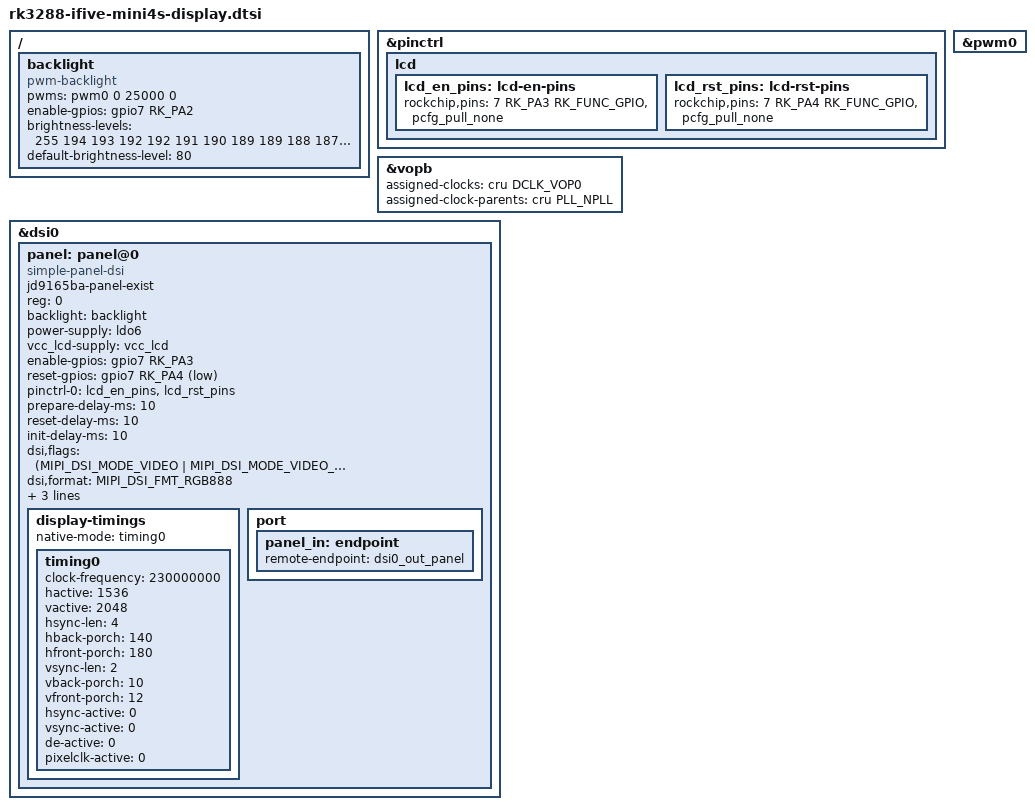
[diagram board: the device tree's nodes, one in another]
// SPDX-License-Identifier: (GPL-2.0+ OR MIT)
/*
 * iFive mini 4S display: backlight, panel power/reset pins, VOPB and the
 * JD9165BA DSI panel.  Included by rk3288-ifive-mini4s.dts.
 */

#include <dt-bindings/display/drm_mipi_dsi.h>
#include <dt-bindings/gpio/gpio.h>

/ {
	backlight: backlight {
		compatible = "pwm-backlight";
		status = "okay";
		pwms = <&pwm0 0 25000 0>;
		enable-gpios = <&gpio7 RK_PA2 GPIO_ACTIVE_HIGH>;
		/*
		 * Inverted drive (duty = 255 - level). The LED driver stays dark
		 * at level 56 and below and lights from about 60 (camera, 2026-11-15);
		 * 4.19 pwm_bl has no min-brightness, so the table holds the floor:
		 * index 0 = off, 1..255 span levels 61..255.
		 */
		brightness-levels = <
			255 194 193 192 192 191 190 189 189 188 187 186 186 185 184 183
			183 182 181 180 179 179 178 177 176 176 175 174 173 173 172 171
			170 170 169 168 167 167 166 165 164 163 163 162 161 160 160 159
			158 157 157 156 155 154 154 153 152 151 150 150 149 148 147 147
			146 145 144 144 143 142 141 141 140 139 138 137 137 136 135 134
			134 133 132 131 131 130 129 128 128 127 126 125 124 124 123 122
			121 121 120 119 118 118 117 116 115 115 114 113 112 112 111 110
			109 108 108 107 106 105 105 104 103 102 102 101 100  99  99  98
			 97  96  95  95  94  93  92  92  91  90  89  89  88  87  86  86
			 85  84  83  82  82  81  80  79  79  78  77  76  76  75  74  73
			 73  72  71  70  70  69  68  67  66  66  65  64  63  63  62  61
			 60  60  59  58  57  57  56  55  54  53  53  52  51  50  50  49
			 48  47  47  46  45  44  44  43  42  41  40  40  39  38  37  37
			 36  35  34  34  33  32  31  31  30  29  28  27  27  26  25  24
			 24  23  22  21  21  20  19  18  18  17  16  15  15  14  13  12
			 11  11  10   9   8   8   7   6   5   5   4   3   2   2   1   0
		>;
		default-brightness-level = <80>;
	};
};

&pinctrl {
	lcd {
		lcd_en_pins: lcd-en-pins {
			rockchip,pins = <7 RK_PA3 RK_FUNC_GPIO &pcfg_pull_none>;
		};

		lcd_rst_pins: lcd-rst-pins {
			rockchip,pins = <7 RK_PA4 RK_FUNC_GPIO &pcfg_pull_none>;
		};
	};
};

&pwm0 {
	status = "okay";
};

/*
 * dclk_vop0 from NPLL (460 MHz / 2 = 230 MHz pixel clock); GPLL (594 MHz)
 * has no integer divider that gives 230 MHz.
 */
&vopb {
	assigned-clocks = <&cru DCLK_VOP0>;
	assigned-clock-parents = <&cru PLL_NPLL>;
	status = "okay";
};

&dsi0 {
	panel: panel@0 {
		jd9165ba-panel-exist;
		compatible = "simple-panel-dsi";
		reg = <0>;
		backlight = <&backlight>;
		power-supply = <&ldo6>;
		vcc_lcd-supply = <&vcc_lcd>;
		enable-gpios = <&gpio7 RK_PA3 GPIO_ACTIVE_HIGH>;
		reset-gpios = <&gpio7 RK_PA4 GPIO_ACTIVE_LOW>;
		pinctrl-names = "default";
		pinctrl-0 = <&lcd_en_pins &lcd_rst_pins>;
		prepare-delay-ms = <10>;
		reset-delay-ms = <10>;
		init-delay-ms = <10>;
		/* Video mode, burst, LPM transfers. */
		dsi,flags = <(MIPI_DSI_MODE_VIDEO | MIPI_DSI_MODE_VIDEO_BURST | MIPI_DSI_MODE_LPM)>;
		dsi,format = <MIPI_DSI_FMT_RGB888>;
		dsi,lanes = <8>;

		/* Panel init commands, packed as big-endian byte words. */
		panel-init-sequence = <0x15000251 0xff150002 0x55021500 0x02532c15
				       0x00023500 0x05780111 0x050a0129>;

		display-timings {
			native-mode = <&timing0>;

			timing0: timing0 {
				clock-frequency = <230000000>;
				hactive = <1536>;
				vactive = <2048>;
				hsync-len = <4>;
				hback-porch = <140>;
				hfront-porch = <180>;
				vsync-len = <2>;
				vback-porch = <10>;
				vfront-porch = <12>;
				hsync-active = <0>;
				vsync-active = <0>;
				de-active = <0>;
				pixelclk-active = <0>;
			};
		};

		port {
			panel_in: endpoint {
				remote-endpoint = <&dsi0_out_panel>;
			};
		};
	};
};
